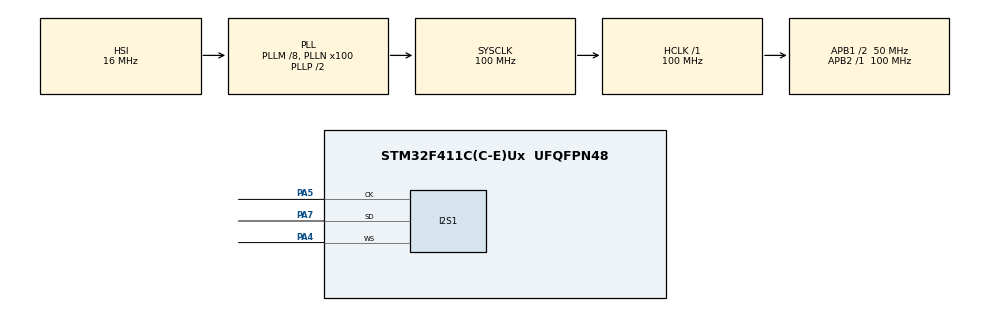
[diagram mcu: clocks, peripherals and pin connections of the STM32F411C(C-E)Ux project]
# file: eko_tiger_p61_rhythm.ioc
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Dma.Request0=SPI1_TX
Dma.SPI1_TX.0.Direction=DMA_MEMORY_TO_PERIPH
Dma.SPI1_TX.0.FIFOMode=DMA_FIFOMODE_DISABLE
Dma.SPI1_TX.0.Instance=DMA2_Stream2
Dma.SPI1_TX.0.MemDataAlignment=DMA_MDATAALIGN_HALFWORD
Dma.SPI1_TX.0.MemInc=DMA_MINC_ENABLE
Dma.SPI1_TX.0.Mode=DMA_CIRCULAR
Dma.SPI1_TX.0.PeriphDataAlignment=DMA_PDATAALIGN_HALFWORD
Dma.SPI1_TX.0.PeriphInc=DMA_PINC_DISABLE
Dma.SPI1_TX.0.Priority=DMA_PRIORITY_VERY_HIGH
I2S1.AudioFreq=I2S_AUDIOFREQ_44K
I2S1.DataFormat=I2S_DATAFORMAT_32B
I2S1.ErrorAudioFreq=0.26 %
I2S1.FullDuplexMode=I2S_FULLDUPLEXMODE_DISABLE
I2S1.Instance=SPI$Index
I2S1.RealAudioFreq=44.117 KHz
I2S1.VirtualMode=I2S_MODE_SLAVE
Mcu.Family=STM32F4
Mcu.Name=STM32F411C(C-E)Ux
Mcu.Package=UFQFPN48
NVIC.DMA2_Stream2_IRQn=true\:0\:0\:false\:false\:true\:false\:true\:true
NVIC.PriorityGroup=NVIC_PRIORITYGROUP_4
PA4.Mode=Half_Duplex_Slave
PA4.Signal=I2S1_WS
PA5.Mode=Half_Duplex_Slave
PA5.Signal=I2S1_CK
PA7.Mode=Half_Duplex_Slave
PA7.Signal=I2S1_SD
ProjectManager.HeapSize=0x200
ProjectManager.StackSize=0x400
ProjectManager.TargetToolchain=STM32CubeIDE
RCC.48MHZClocksFreq_Value=50000000
RCC.AHBFreq_Value=100000000
RCC.APB1CLKDivider=RCC_HCLK_DIV2
RCC.APB1Freq_Value=50000000
RCC.APB1TimFreq_Value=100000000
RCC.APB2Freq_Value=100000000
RCC.APB2TimFreq_Value=100000000
RCC.CortexFreq_Value=100000000
RCC.HCLKFreq_Value=100000000
RCC.HSE_VALUE=25000000
RCC.HSI_VALUE=16000000
RCC.LSE_VALUE=32768
RCC.PLLM=8
RCC.PLLN=100
RCC.SYSCLKFreq_VALUE=100000000
RCC.SYSCLKSource=RCC_SYSCLKSOURCE_PLLCLK
RCC.VCOOutputFreq_Value=200000000
board=custom

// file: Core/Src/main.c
/* USER CODE BEGIN Header */
/**
  ******************************************************************************
  * @file           : main.c
  * @brief          : Main program body
  ******************************************************************************
  * @attention
  *
  * Copyright (c) 2024 STMicroelectronics.
  * All rights reserved.
  *
  * This software is licensed under terms that can be found in the LICENSE file
  * in the root directory of this software component.
  * If no LICENSE file comes with this software, it is provided AS-IS.
  *
  ******************************************************************************
  */
/* USER CODE END Header */
#include "main.h"
#include "dma.h"
#include "i2s.h"
#include "gpio.h"

/* USER CODE BEGIN Includes */
#include "eko_tiger_p61_rhythm.h"

/* USER CODE END Includes */

void SystemClock_Config(void);

int main(void)
{

  /* MCU Configuration--------------------------------------------------------*/

  /* Reset of all peripherals, Initializes the Flash interface and the Systick. */
  HAL_Init();

  /* Configure the system clock */
  SystemClock_Config();

  /* Initialize all configured peripherals */
  MX_GPIO_Init();
  MX_DMA_Init();
  MX_I2S1_Init();
  /* USER CODE BEGIN 2 */

  eko_tiger_p61_rhythm_setup();

  /* USER CODE END 2 */

  /* Infinite loop */
  /* USER CODE BEGIN WHILE */
  eko_tiger_p61_rhythm_loop();
    /* USER CODE END WHILE */

}

void SystemClock_Config(void)
{
  RCC_OscInitTypeDef RCC_OscInitStruct = {0};
  RCC_ClkInitTypeDef RCC_ClkInitStruct = {0};

  /** Configure the main internal regulator output voltage
  */
  __HAL_RCC_PWR_CLK_ENABLE();
  __HAL_PWR_VOLTAGESCALING_CONFIG(PWR_REGULATOR_VOLTAGE_SCALE1);

  /** Initializes the RCC Oscillators according to the specified parameters
  * in the RCC_OscInitTypeDef structure.
  */
  RCC_OscInitStruct.OscillatorType = RCC_OSCILLATORTYPE_HSI;
  RCC_OscInitStruct.HSIState = RCC_HSI_ON;
  RCC_OscInitStruct.HSICalibrationValue = RCC_HSICALIBRATION_DEFAULT;
  RCC_OscInitStruct.PLL.PLLState = RCC_PLL_ON;
  RCC_OscInitStruct.PLL.PLLSource = RCC_PLLSOURCE_HSI;
  RCC_OscInitStruct.PLL.PLLM = 8;
  RCC_OscInitStruct.PLL.PLLN = 100;
  RCC_OscInitStruct.PLL.PLLP = RCC_PLLP_DIV2;
  RCC_OscInitStruct.PLL.PLLQ = 4;
  if (HAL_RCC_OscConfig(&RCC_OscInitStruct) != HAL_OK)
  {
    Error_Handler();
  }

  /** Initializes the CPU, AHB and APB buses clocks
  */
  RCC_ClkInitStruct.ClockType = RCC_CLOCKTYPE_HCLK|RCC_CLOCKTYPE_SYSCLK
                              |RCC_CLOCKTYPE_PCLK1|RCC_CLOCKTYPE_PCLK2;
  RCC_ClkInitStruct.SYSCLKSource = RCC_SYSCLKSOURCE_PLLCLK;
  RCC_ClkInitStruct.AHBCLKDivider = RCC_SYSCLK_DIV1;
  RCC_ClkInitStruct.APB1CLKDivider = RCC_HCLK_DIV2;
  RCC_ClkInitStruct.APB2CLKDivider = RCC_HCLK_DIV1;

  if (HAL_RCC_ClockConfig(&RCC_ClkInitStruct, FLASH_LATENCY_3) != HAL_OK)
  {
    Error_Handler();
  }
}

void Error_Handler(void)
{
  __disable_irq();
  while (1)
  {
  }
}
